AUTOSAR XML (schema 314)
package /ComponentType
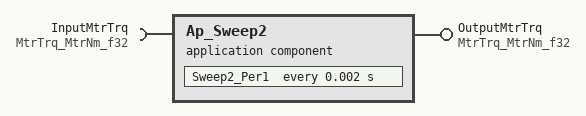
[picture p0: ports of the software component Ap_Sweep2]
  application software component type Ap_Sweep2
    provide port OutputMtrTrq: unqueued-sender-com-spec{data-element=MtrNm_f32, can-invalidate=false, init-value=D_ZERO_ULS_F32}, provided-interface=MtrTrq_MtrNm_f32
    require port InputMtrTrq: unqueued-receiver-com-spec{data-element=MtrNm_f32, init-value=D_ZERO_ULS_F32}, required-interface=MtrTrq_MtrNm_f32
  internal behavior Ap_Sweep2_InternalBehavior: component=Ap_Sweep2
    timing event TMT_Sweep2_Per1: start-on-event=Sweep2_Per1, period=0.002
    port-api-options:
      enable-take-address=false, indirect-api=false, port=InputMtrTrq
      enable-take-address=false, indirect-api=false, port=OutputMtrTrq
    runnable Sweep2_Per1
      data read access READ_InputMtrTrq_MtrNm_f32: data-element=InputMtrTrq.MtrNm_f32
      data write access WRITE_OutputMtrTrq_MtrNm_f32: data-element=OutputMtrTrq.MtrNm_f32
  swc implementation Ap_Sweep2_Implementation: behavior=Ap_Sweep2_InternalBehavior
    code-descriptors:
      code Code: type=SRC
